VERSION "demo-dbc-v1"

NS_ :

BS_:

BU_: ECU_GW ECU_ENG ECU_BRK

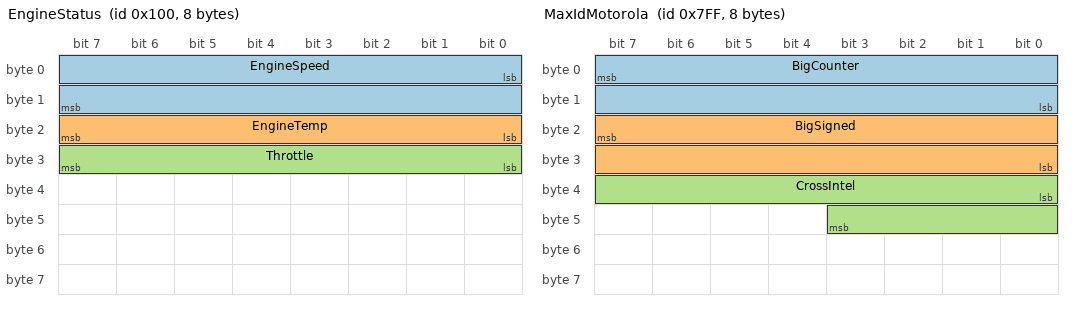
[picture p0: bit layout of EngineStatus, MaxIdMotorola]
BO_ 256 EngineStatus: 8 ECU_ENG
 SG_ EngineSpeed : 0|16@1+ (0.25,0) [0|16383.75] "rpm" ECU_GW
 SG_ EngineTemp : 16|8@1- (1,-40) [-40|215] "degC" ECU_GW
 SG_ Throttle : 24|8@1+ (0.5,0) [0|100] "%" ECU_GW

BO_ 300 BrakeMux: 8 ECU_BRK
 SG_ BrakeMux M : 0|4@1+ (1,0) [0|15] "" ECU_GW
 SG_ PedalPos m1 : 8|8@1+ (1,0) [0|100] "%" ECU_GW
 SG_ BrakePress m1 : 16|16@1+ (0.1,0) [0|6000] "kPa" ECU_GW
 SG_ LineVoltage m2 : 47|12@0+ (0.01,0) [0|40.95] "V" ECU_GW
 SG_ ErrorCode m2 : 32|4@1+ (1,0) [0|15] "" ECU_GW
BO_ 2047 MaxIdMotorola: 8 ECU_GW
 SG_ BigCounter : 7|16@0+ (1,0) [0|65535] "" Vector__XXX
 SG_ BigSigned : 23|16@0- (1,0) [-32768|32767] "" Vector__XXX
 SG_ CrossIntel : 32|12@1+ (0.1,-50) [-50|3595.9] "deg" Vector__XXX

CM_ BO_ 256 "Engine status frame for demo / hand-checkable tests";
CM_ SG_ 300 BrakeMux "single-level multiplexor: 1=pedal branch, 2=voltage branch";
